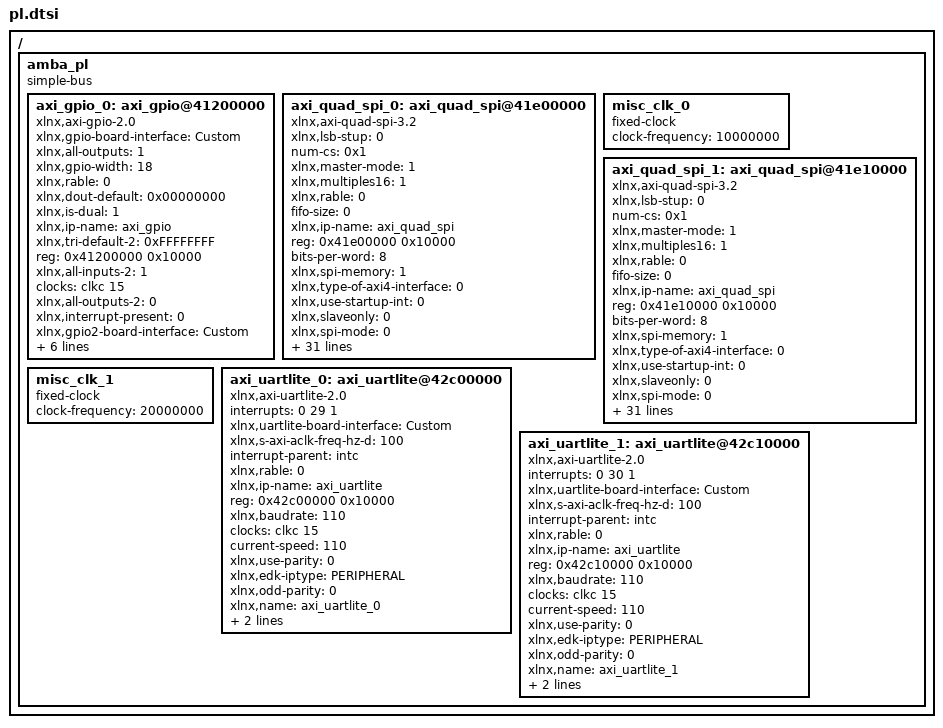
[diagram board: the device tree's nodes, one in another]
/ {
	amba_pl: amba_pl {
		ranges;
		compatible = "simple-bus";
		#address-cells = <1>;
		#size-cells = <1>;
		axi_gpio_0: axi_gpio@41200000 {
			xlnx,gpio-board-interface = "Custom";
			compatible = "xlnx,axi-gpio-2.0" , "xlnx,xps-gpio-1.00.a";
			xlnx,all-outputs = <1>;
			xlnx,gpio-width = <18>;
			xlnx,rable = <0>;
			xlnx,dout-default = <0x00000000>;
			xlnx,is-dual = <1>;
			xlnx,ip-name = "axi_gpio";
			xlnx,tri-default-2 = <0xFFFFFFFF>;
			reg = <0x41200000 0x10000>;
			xlnx,all-inputs-2 = <1>;
			clocks = <&clkc 15>;
			xlnx,all-outputs-2 = <0>;
			xlnx,interrupt-present = <0>;
			xlnx,gpio2-board-interface = "Custom";
			xlnx,edk-iptype = "PERIPHERAL";
			xlnx,dout-default-2 = <0x00000000>;
			xlnx,gpio2-width = <7>;
			status = "okay";
			clock-names = "s_axi_aclk";
			xlnx,tri-default = <0xFFFFFFFF>;
			xlnx,name = "axi_gpio_0";
			xlnx,all-inputs = <0>;
		};
		axi_quad_spi_0: axi_quad_spi@41e00000 {
			xlnx,lsb-stup = <0>;
			num-cs = <0x1>;
			xlnx,master-mode = <1>;
			xlnx,multiples16 = <1>;
			xlnx,rable = <0>;
			fifo-size = <0>;
			xlnx,ip-name = "axi_quad_spi";
			reg = <0x41e00000 0x10000>;
			bits-per-word = <8>;
			xlnx,spi-memory = <1>;
			xlnx,type-of-axi4-interface = <0>;
			xlnx,use-startup-int = <0>;
			xlnx,slaveonly = <0>;
			xlnx,spi-mode = <0>;
			interrupt-names = "ip2intc_irpt";
			compatible = "xlnx,axi-quad-spi-3.2" , "xlnx,xps-spi-2.00.a";
			xlnx,byte-level-interrupt-en = <0>;
			xlnx,s-axi4-addr-width = <24>;
			xlnx,sck-ratio = <4>;
			interrupt-parent = <&intc>;
			xlnx,async-clk = <1>;
			status = "okay";
			xlnx,sck-ratio1 = <1>;
			xlnx,fifo-included = <0>;
			xlnx,name = "axi_quad_spi_0";
			interrupts = < 0 31 1 >;
			xlnx,use-startup-ext = <0>;
			xlnx,hasfifos = <0>;
			xlnx,s-axi4-id-width = <4>;
			xlnx,shared-startup = <0>;
			xlnx,new-seq-en = <1>;
			xlnx,qspi-board-interface = "Custom";
			clocks = <&misc_clk_0>, <&clkc 15>;
			xlnx,edk-iptype = "PERIPHERAL";
			xlnx,fifo-depth = <0>;
			clock-names = "ext_spi_clk" , "s_axi_aclk";
			xlnx,axi-interface = <0>;
			xlnx,num-ss-bits = <0x1>;
			xlnx,select-xpm = <0>;
			xlnx,xip-mode = <0>;
			xlnx,xip-perf-mode = <1>;
			xlnx,dual-quad-mode = <0>;
			xlnx,num-transfer-bits = <8>;
			xlnx,s-axi4-data-width = <32>;
			xlnx,use-startup = <0>;
			xlnx,spi-mem-addr-bits = <24>;
			xlnx,uc-family = <0>;
			xlnx,Axi4-address = <0>;
			xlnx,sub-family = "zynq";
		};
		misc_clk_0: misc_clk_0 {
			compatible = "fixed-clock";
			clock-frequency = <10000000>;
			#clock-cells = <0>;
		};
		axi_quad_spi_1: axi_quad_spi@41e10000 {
			xlnx,lsb-stup = <0>;
			num-cs = <0x1>;
			xlnx,master-mode = <1>;
			xlnx,multiples16 = <1>;
			xlnx,rable = <0>;
			fifo-size = <0>;
			xlnx,ip-name = "axi_quad_spi";
			reg = <0x41e10000 0x10000>;
			bits-per-word = <8>;
			xlnx,spi-memory = <1>;
			xlnx,type-of-axi4-interface = <0>;
			xlnx,use-startup-int = <0>;
			xlnx,slaveonly = <0>;
			xlnx,spi-mode = <0>;
			interrupt-names = "ip2intc_irpt";
			compatible = "xlnx,axi-quad-spi-3.2" , "xlnx,xps-spi-2.00.a";
			xlnx,byte-level-interrupt-en = <0>;
			xlnx,s-axi4-addr-width = <24>;
			xlnx,sck-ratio = <2>;
			interrupt-parent = <&intc>;
			xlnx,async-clk = <1>;
			status = "okay";
			xlnx,sck-ratio1 = <1>;
			xlnx,fifo-included = <0>;
			xlnx,name = "axi_quad_spi_1";
			interrupts = < 0 32 1 >;
			xlnx,use-startup-ext = <0>;
			xlnx,hasfifos = <0>;
			xlnx,s-axi4-id-width = <4>;
			xlnx,shared-startup = <0>;
			xlnx,new-seq-en = <1>;
			xlnx,qspi-board-interface = "Custom";
			clocks = <&misc_clk_1>, <&clkc 15>;
			xlnx,edk-iptype = "PERIPHERAL";
			xlnx,fifo-depth = <0>;
			clock-names = "ext_spi_clk" , "s_axi_aclk";
			xlnx,axi-interface = <0>;
			xlnx,num-ss-bits = <0x1>;
			xlnx,select-xpm = <0>;
			xlnx,xip-mode = <0>;
			xlnx,xip-perf-mode = <1>;
			xlnx,dual-quad-mode = <0>;
			xlnx,num-transfer-bits = <8>;
			xlnx,s-axi4-data-width = <32>;
			xlnx,use-startup = <0>;
			xlnx,spi-mem-addr-bits = <24>;
			xlnx,uc-family = <0>;
			xlnx,Axi4-address = <0>;
			xlnx,sub-family = "zynq";
		};
		misc_clk_1: misc_clk_1 {
			compatible = "fixed-clock";
			clock-frequency = <20000000>;
			#clock-cells = <0>;
		};
		axi_uartlite_0: axi_uartlite@42c00000 {
			interrupts = < 0 29 1 >;
			compatible = "xlnx,axi-uartlite-2.0" , "xlnx,xps-uartlite-1.00.a";
			xlnx,uartlite-board-interface = "Custom";
			xlnx,s-axi-aclk-freq-hz-d = <100>;
			interrupt-parent = <&intc>;
			xlnx,rable = <0>;
			xlnx,ip-name = "axi_uartlite";
			reg = <0x42c00000 0x10000>;
			xlnx,baudrate = <110>;
			clocks = <&clkc 15>;
			current-speed = <110>;
			xlnx,use-parity = <0>;
			xlnx,edk-iptype = "PERIPHERAL";
			xlnx,odd-parity = <0>;
			status = "okay";
			clock-names = "s_axi_aclk";
			interrupt-names = "interrupt";
			xlnx,name = "axi_uartlite_0";
			xlnx,data-bits = <8>;
			xlnx,parity = "No_Parity";
		};
		axi_uartlite_1: axi_uartlite@42c10000 {
			interrupts = < 0 30 1 >;
			compatible = "xlnx,axi-uartlite-2.0" , "xlnx,xps-uartlite-1.00.a";
			xlnx,uartlite-board-interface = "Custom";
			xlnx,s-axi-aclk-freq-hz-d = <100>;
			interrupt-parent = <&intc>;
			xlnx,rable = <0>;
			xlnx,ip-name = "axi_uartlite";
			reg = <0x42c10000 0x10000>;
			xlnx,baudrate = <110>;
			clocks = <&clkc 15>;
			current-speed = <110>;
			xlnx,use-parity = <0>;
			xlnx,edk-iptype = "PERIPHERAL";
			xlnx,odd-parity = <0>;
			status = "okay";
			clock-names = "s_axi_aclk";
			interrupt-names = "interrupt";
			xlnx,name = "axi_uartlite_1";
			xlnx,data-bits = <8>;
			xlnx,parity = "No_Parity";
		};
	};
};
